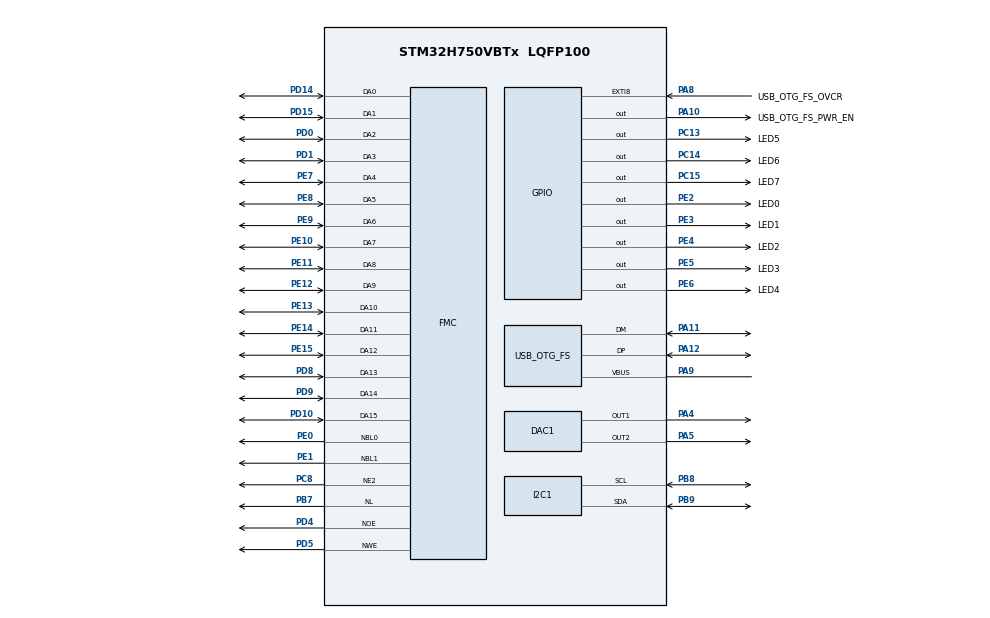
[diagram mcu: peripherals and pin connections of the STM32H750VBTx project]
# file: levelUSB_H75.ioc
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DAC1.DAC_Channel-DAC_OUT1=DAC_CHANNEL_1
DAC1.DAC_Channel-DAC_OUT2=DAC_CHANNEL_2
FATFS._FS_EXFAT=1
FATFS._USE_LFN=3
FATFS._USE_MUTEX=1
FMC.WriteOperation1=FMC_WRITE_OPERATION_ENABLE
FREERTOS.Tasks01=StartupTask,24,128,startupTask,Default,NULL,Dynamic,NULL,NULL
FREERTOS.configUSE_NEWLIB_REENTRANT=1
I2C1.Timing=0x109093DC
Mcu.Family=STM32H7
Mcu.Name=STM32H750VBTx
Mcu.Package=LQFP100
Mdma.MDMA_Channel0.Request0=SW
Mdma.MDMA_Channel0.RequestsNb=1
Mdma.MDMA_Channel0.SW.0.BlockCount=0
Mdma.MDMA_Channel0.SW.0.BlockDataLength=0
Mdma.MDMA_Channel0.SW.0.BufferTransferLength=1
Mdma.MDMA_Channel0.SW.0.CircularMode=MDMA_LINEAR_LIST
Mdma.MDMA_Channel0.SW.0.DataAlignment=MDMA_DATAALIGN_PACKENABLE
Mdma.MDMA_Channel0.SW.0.DestBlockAddressOffset=0
Mdma.MDMA_Channel0.SW.0.DestBurst=MDMA_DEST_BURST_SINGLE
Mdma.MDMA_Channel0.SW.0.DestDataSize=MDMA_DEST_DATASIZE_BYTE
Mdma.MDMA_Channel0.SW.0.DestinationInc=MDMA_DEST_INC_BYTE
Mdma.MDMA_Channel0.SW.0.DstAddress=0
Mdma.MDMA_Channel0.SW.0.Endianness=MDMA_LITTLE_ENDIANNESS_PRESERVE
Mdma.MDMA_Channel0.SW.0.Instance=MDMA_Channel0
Mdma.MDMA_Channel0.SW.0.MaskAddress=0
Mdma.MDMA_Channel0.SW.0.MaskData=0
Mdma.MDMA_Channel0.SW.0.Priority=MDMA_PRIORITY_LOW
Mdma.MDMA_Channel0.SW.0.Rank=First
Mdma.MDMA_Channel0.SW.0.SourceBlockAddressOffset=0
Mdma.MDMA_Channel0.SW.0.SourceBurst=MDMA_SOURCE_BURST_SINGLE
Mdma.MDMA_Channel0.SW.0.SourceDataSize=MDMA_SRC_DATASIZE_BYTE
Mdma.MDMA_Channel0.SW.0.SourceInc=MDMA_SRC_INC_BYTE
Mdma.MDMA_Channel0.SW.0.SrcAddress=0
Mdma.MDMA_Channel0.SW.0.TransferTriggerMode=MDMA_BUFFER_TRANSFER
Mdma.MDMA_Channel1.Request0=SW
Mdma.MDMA_Channel1.RequestsNb=1
Mdma.MDMA_Channel1.SW.0.BlockCount=0
Mdma.MDMA_Channel1.SW.0.BlockDataLength=0
Mdma.MDMA_Channel1.SW.0.BufferTransferLength=1
Mdma.MDMA_Channel1.SW.0.CircularMode=MDMA_LINEAR_LIST
Mdma.MDMA_Channel1.SW.0.DataAlignment=MDMA_DATAALIGN_PACKENABLE
Mdma.MDMA_Channel1.SW.0.DestBlockAddressOffset=0
Mdma.MDMA_Channel1.SW.0.DestBurst=MDMA_DEST_BURST_SINGLE
Mdma.MDMA_Channel1.SW.0.DestDataSize=MDMA_DEST_DATASIZE_BYTE
Mdma.MDMA_Channel1.SW.0.DestinationInc=MDMA_DEST_INC_BYTE
Mdma.MDMA_Channel1.SW.0.DstAddress=0
Mdma.MDMA_Channel1.SW.0.Endianness=MDMA_LITTLE_ENDIANNESS_PRESERVE
Mdma.MDMA_Channel1.SW.0.Instance=MDMA_Channel1
Mdma.MDMA_Channel1.SW.0.MaskAddress=0
Mdma.MDMA_Channel1.SW.0.MaskData=0
Mdma.MDMA_Channel1.SW.0.Priority=MDMA_PRIORITY_LOW
Mdma.MDMA_Channel1.SW.0.Rank=First
Mdma.MDMA_Channel1.SW.0.SourceBlockAddressOffset=0
Mdma.MDMA_Channel1.SW.0.SourceBurst=MDMA_SOURCE_BURST_SINGLE
Mdma.MDMA_Channel1.SW.0.SourceDataSize=MDMA_SRC_DATASIZE_BYTE
Mdma.MDMA_Channel1.SW.0.SourceInc=MDMA_SRC_INC_BYTE
Mdma.MDMA_Channel1.SW.0.SrcAddress=0
Mdma.MDMA_Channel1.SW.0.TransferTriggerMode=MDMA_BUFFER_TRANSFER
Mdma.RequestSet0=MDMA_Channel0
Mdma.RequestSet1=MDMA_Channel1
Mdma.RequestSetsNb=2
NVIC.MDMA_IRQn=true\:5\:0\:false\:false\:true\:false\:false\:true
NVIC.OTG_FS_IRQn=true\:5\:0\:false\:false\:true\:true\:false\:true
NVIC.PriorityGroup=NVIC_PRIORITYGROUP_4
NVIC.TIM6_DAC_IRQn=true\:15\:0\:false\:false\:true\:false\:false\:true
NVIC.TIM7_IRQn=true\:5\:0\:false\:false\:true\:true\:true\:true
NVIC.TimeBase=TIM6_DAC_IRQn
NVIC.TimeBaseIP=TIM6
PA10.GPIO_Label=USB_OTG_FS_PWR_EN
PA10.Signal=GPIO_Output
PA11.Mode=Host_Only
PA11.Signal=USB_OTG_FS_DM
PA12.Mode=Host_Only
PA12.Signal=USB_OTG_FS_DP
PA13\ (JTMS/SWDIO).Mode=Serial_Wire
PA13\ (JTMS/SWDIO).Signal=DEBUG_JTMS-SWDIO
PA14\ (JTCK/SWCLK).Mode=Serial_Wire
PA14\ (JTCK/SWCLK).Signal=DEBUG_JTCK-SWCLK
PA4.Signal=COMP_DAC11_group
PA5.Signal=COMP_DAC12_group
PA8.GPIO_Label=USB_OTG_FS_OVCR
PA8.Signal=GPXTI8
PA9.Mode=Activate_VBUS
PA9.Signal=USB_OTG_FS_VBUS
PB7.Signal=FMC_NL
PB8.Mode=I2C
PB8.Signal=I2C1_SCL
PB9.Mode=I2C
PB9.Signal=I2C1_SDA
PC13.GPIO_Label=LED5
PC13.Signal=GPIO_Output
PC14-OSC32_IN\ (OSC32_IN).GPIO_Label=LED6
PC14-OSC32_IN\ (OSC32_IN).Signal=GPIO_Output
PC15-OSC32_OUT\ (OSC32_OUT).GPIO_Label=LED7
PC15-OSC32_OUT\ (OSC32_OUT).Signal=GPIO_Output
PC8.Mode=NorPsramChipSelect2_1
PC8.Signal=FMC_NE2
PD0.Signal=FMC_D2_DA2
PD1.Signal=FMC_D3_DA3
PD10.Signal=FMC_D15_DA15
PD14.Signal=FMC_D0_DA0
PD15.Signal=FMC_D1_DA1
PD4.Signal=FMC_NOE
PD5.Signal=FMC_NWE
PD8.Signal=FMC_D13_DA13
PD9.Signal=FMC_D14_DA14
PE0.Signal=FMC_NBL0
PE1.Signal=FMC_NBL1
PE10.Signal=FMC_D7_DA7
PE11.Signal=FMC_D8_DA8
PE12.Signal=FMC_D9_DA9
PE13.Signal=FMC_D10_DA10
PE14.Signal=FMC_D11_DA11
PE15.Signal=FMC_D12_DA12
PE2.GPIO_Label=LED0
PE2.Signal=GPIO_Output
PE3.GPIO_Label=LED1
PE3.Signal=GPIO_Output
PE4.GPIO_Label=LED2
PE4.Signal=GPIO_Output
PE5.GPIO_Label=LED3
PE5.Signal=GPIO_Output
PE6.GPIO_Label=LED4
PE6.Signal=GPIO_Output
PE7.Signal=FMC_D4_DA4
PE8.Signal=FMC_D5_DA5
PE9.Signal=FMC_D6_DA6
PH0-OSC_IN\ (PH0).Mode=HSE-External-Oscillator
PH0-OSC_IN\ (PH0).Signal=RCC_OSC_IN
PH1-OSC_OUT\ (PH1).Mode=HSE-External-Oscillator
PH1-OSC_OUT\ (PH1).Signal=RCC_OSC_OUT
ProjectManager.HeapSize=0x200
ProjectManager.StackSize=0x400
ProjectManager.TargetToolchain=Makefile
RCC.ADCFreq_Value=16125000
RCC.APB1Freq_Value=120000000
RCC.APB2Freq_Value=120000000
RCC.APB3Freq_Value=120000000
RCC.APB4Freq_Value=120000000
RCC.CortexFreq_Value=240000000
RCC.DIVM1=2
RCC.DIVM3=4
RCC.DIVN1=120
RCC.DIVN3=75
RCC.DIVQ1=8
RCC.HCLKFreq_Value=120000000
RCC.HPRE=RCC_HCLK_DIV2
RCC.HSE_VALUE=8000000
RCC.I2C123CLockSelection=RCC_I2C123CLKSOURCE_PLL3
RCC.PLLSourceVirtual=RCC_PLLSOURCE_HSE
RCC.SYSCLKFreq_VALUE=240000000
RCC.SYSCLKSource=RCC_SYSCLKSOURCE_PLLCLK
RCC.USBFreq_Value=60000000
SH.COMP_DAC11_group.0=DAC1_OUT1,DAC_OUT1
SH.COMP_DAC12_group.0=DAC1_OUT2,DAC_OUT2
SH.FMC_D0_DA0.0=FMC_DA0,16b-da1
SH.FMC_D10_DA10.0=FMC_DA10,16b-da1
SH.FMC_D11_DA11.0=FMC_DA11,16b-da1
SH.FMC_D12_DA12.0=FMC_DA12,16b-da1
SH.FMC_D13_DA13.0=FMC_DA13,16b-da1
SH.FMC_D14_DA14.0=FMC_DA14,16b-da1
SH.FMC_D15_DA15.0=FMC_DA15,16b-da1
SH.FMC_D1_DA1.0=FMC_DA1,16b-da1
SH.FMC_D2_DA2.0=FMC_DA2,16b-da1
SH.FMC_D3_DA3.0=FMC_DA3,16b-da1
SH.FMC_D4_DA4.0=FMC_DA4,16b-da1
SH.FMC_D5_DA5.0=FMC_DA5,16b-da1
SH.FMC_D6_DA6.0=FMC_DA6,16b-da1
SH.FMC_D7_DA7.0=FMC_DA7,16b-da1
SH.FMC_D8_DA8.0=FMC_DA8,16b-da1
SH.FMC_D9_DA9.0=FMC_DA9,16b-da1
SH.FMC_NBL0.0=FMC_NBL0,2ByteEnable1
SH.FMC_NBL1.0=FMC_NBL1,2ByteEnable1
SH.FMC_NL.0=FMC_NL,AddressValid1
SH.FMC_NOE.0=FMC_NOE,MuxedPsram1
SH.FMC_NWE.0=FMC_NWE,MuxedPsram1
TIM7.AutoReloadPreload=TIM_AUTORELOAD_PRELOAD_ENABLE
TIM7.Period=2499
TIM7.TIM_MasterOutputTrigger=TIM_TRGO_UPDATE
USB_HOST.BSP.number=1
USB_HOST.USBH_HandleTypeDef-MSC_FS=hUsbHostFS
USB_HOST.VirtualModeFS=Msc
USB_HOST0.BSP.STBoard=false
USB_HOST0.BSP.api=Unknown
USB_HOST0.BSP.i2caddr=0
USB_HOST0.BSP.instance=PA10
USB_HOST0.BSP.ip=GPIO
USB_HOST0.BSP.mode=Output
USB_HOST0.BSP.name=Drive_VBUS_FS
USB_HOST0.BSP.solution=PA10
USB_OTG_FS.VirtualMode=Host_Only
USB_OTG_FS.dma_enable=ENABLE
USB_OTG_FS.phy_itface=HCD_PHY_EMBEDDED
VP_FATFS_VS_USB.Mode=USB
VP_FREERTOS_VS_CMSIS_V2.Mode=CMSIS_V2
VP_RNG_VS_RNG.Mode=RNG_Activate
VP_SYS_VS_tim6.Mode=TIM6
VP_TIM7_VS_ClockSourceINT.Mode=Enable_Timer
VP_USB_HOST_VS_USB_HOST_MSC_FS.Mode=MSC_FS
board=custom

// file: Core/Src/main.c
/* USER CODE BEGIN Header */
/**
  ******************************************************************************
  * @file           : main.c
  * @brief          : Main program body
  ******************************************************************************
  * @attention
  *
  * <h2><center>&copy; Copyright (c) 2022 STMicroelectronics.
  * All rights reserved.</center></h2>
  *
  * This software component is licensed by ST under Ultimate Liberty license
  * SLA0044, the "License"; You may not use this file except in compliance with
  * the License. You may obtain a copy of the License at:
  *                             www.st.com/SLA0044
  *
  ******************************************************************************
  */
/* USER CODE END Header */
#include "main.h"
#include "cmsis_os.h"
#include "dac.h"
#include "fatfs.h"
#include "i2c.h"
#include "mdma.h"
#include "rng.h"
#include "tim.h"
#include "usb_host.h"
#include "gpio.h"
#include "fmc.h"

void SystemClock_Config(void);
void MX_FREERTOS_Init(void);

int main(void)
{

  /* MCU Configuration--------------------------------------------------------*/

  /* Reset of all peripherals, Initializes the Flash interface and the Systick. */
  HAL_Init();

  /* Configure the system clock */
  SystemClock_Config();

  /* Initialize all configured peripherals */
  MX_GPIO_Init();
  MX_MDMA_Init();
  MX_DAC1_Init();
  MX_FMC_Init();
  MX_I2C1_Init();
  MX_RNG_Init();
  MX_TIM7_Init();
  MX_FATFS_Init();

  /* Init scheduler */
  osKernelInitialize();  /* Call init function for freertos objects (in freertos.c) */
  MX_FREERTOS_Init();
  /* Start scheduler */
  osKernelStart();

  /* We should never get here as control is now taken by the scheduler */
  /* Infinite loop */
  while (1)
  {

  }
}

void SystemClock_Config(void)
{
  RCC_OscInitTypeDef RCC_OscInitStruct = {0};
  RCC_ClkInitTypeDef RCC_ClkInitStruct = {0};

  /** Supply configuration update enable
  */
  HAL_PWREx_ConfigSupply(PWR_LDO_SUPPLY);
  /** Configure the main internal regulator output voltage
  */
  __HAL_PWR_VOLTAGESCALING_CONFIG(PWR_REGULATOR_VOLTAGE_SCALE2);

  while(!__HAL_PWR_GET_FLAG(PWR_FLAG_VOSRDY)) {}
  /** Macro to configure the PLL clock source
  */
  __HAL_RCC_PLL_PLLSOURCE_CONFIG(RCC_PLLSOURCE_HSE);
  /** Initializes the RCC Oscillators according to the specified parameters
  * in the RCC_OscInitTypeDef structure.
  */
  RCC_OscInitStruct.OscillatorType = RCC_OSCILLATORTYPE_HSI48|RCC_OSCILLATORTYPE_HSE;
  RCC_OscInitStruct.HSEState = RCC_HSE_ON;
  RCC_OscInitStruct.HSI48State = RCC_HSI48_ON;
  RCC_OscInitStruct.PLL.PLLState = RCC_PLL_ON;
  RCC_OscInitStruct.PLL.PLLSource = RCC_PLLSOURCE_HSE;
  RCC_OscInitStruct.PLL.PLLM = 2;
  RCC_OscInitStruct.PLL.PLLN = 120;
  RCC_OscInitStruct.PLL.PLLP = 2;
  RCC_OscInitStruct.PLL.PLLQ = 8;
  RCC_OscInitStruct.PLL.PLLR = 2;
  RCC_OscInitStruct.PLL.PLLRGE = RCC_PLL1VCIRANGE_2;
  RCC_OscInitStruct.PLL.PLLVCOSEL = RCC_PLL1VCOWIDE;
  RCC_OscInitStruct.PLL.PLLFRACN = 0;
  if (HAL_RCC_OscConfig(&RCC_OscInitStruct) != HAL_OK)
  {
    Error_Handler();
  }
  /** Initializes the CPU, AHB and APB buses clocks
  */
  RCC_ClkInitStruct.ClockType = RCC_CLOCKTYPE_HCLK|RCC_CLOCKTYPE_SYSCLK
                              |RCC_CLOCKTYPE_PCLK1|RCC_CLOCKTYPE_PCLK2
                              |RCC_CLOCKTYPE_D3PCLK1|RCC_CLOCKTYPE_D1PCLK1;
  RCC_ClkInitStruct.SYSCLKSource = RCC_SYSCLKSOURCE_PLLCLK;
  RCC_ClkInitStruct.SYSCLKDivider = RCC_SYSCLK_DIV1;
  RCC_ClkInitStruct.AHBCLKDivider = RCC_HCLK_DIV2;
  RCC_ClkInitStruct.APB3CLKDivider = RCC_APB3_DIV1;
  RCC_ClkInitStruct.APB1CLKDivider = RCC_APB1_DIV1;
  RCC_ClkInitStruct.APB2CLKDivider = RCC_APB2_DIV1;
  RCC_ClkInitStruct.APB4CLKDivider = RCC_APB4_DIV1;

  if (HAL_RCC_ClockConfig(&RCC_ClkInitStruct, FLASH_LATENCY_2) != HAL_OK)
  {
    Error_Handler();
  }
}

void HAL_TIM_PeriodElapsedCallback(TIM_HandleTypeDef *htim)
{
  if (htim->Instance == TIM6) {
    HAL_IncTick();
  }
}

void Error_Handler(void)
{
  __disable_irq();
  while (1)
  {
  }
}

/************************ (C) COPYRIGHT STMicroelectronics *****END OF FILE****/

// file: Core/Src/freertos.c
/* USER CODE BEGIN Header */
/**
  ******************************************************************************
  * File Name          : freertos.c
  * Description        : Code for freertos applications
  ******************************************************************************
  * @attention
  *
  * <h2><center>&copy; Copyright (c) 2022 STMicroelectronics.
  * All rights reserved.</center></h2>
  *
  * This software component is licensed by ST under Ultimate Liberty license
  * SLA0044, the "License"; You may not use this file except in compliance with
  * the License. You may obtain a copy of the License at:
  *                             www.st.com/SLA0044
  *
  ******************************************************************************
  */
/* USER CODE END Header */

#include "FreeRTOS.h"
#include "task.h"
#include "main.h"
#include "cmsis_os.h"

/* USER CODE BEGIN Includes */
#include "sparkboxStartup.hpp"
/* USER CODE END Includes */

/* Definitions for StartupTask */
osThreadId_t StartupTaskHandle;
const osThreadAttr_t StartupTask_attributes = {
  .name = "StartupTask",
  .stack_size = 128 * 4,
  .priority = (osPriority_t) osPriorityNormal,
};

void startupTask(void *argument);

extern void MX_USB_HOST_Init(void);
void MX_FREERTOS_Init(void); /* (MISRA C 2004 rule 8.1) */

void MX_FREERTOS_Init(void) {

  /* Create the thread(s) */
  /* creation of StartupTask */
  StartupTaskHandle = osThreadNew(startupTask, NULL, &StartupTask_attributes);

}

void startupTask(void *argument)
{
  /* init code for USB_HOST */
  MX_USB_HOST_Init();
  for(;;)
  {
    osDelay(1);
  }
}

/************************ (C) COPYRIGHT STMicroelectronics *****END OF FILE****/
